AUTOSAR XML (schema 4-0-3)
package /ComponentTypes
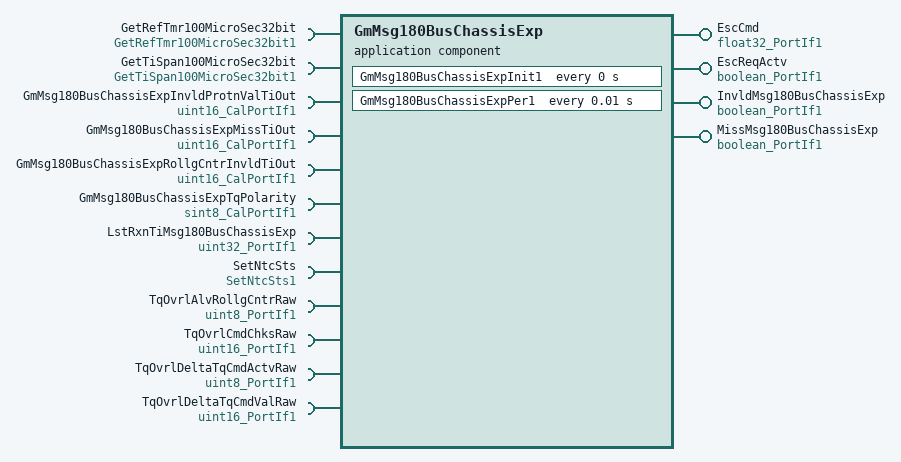
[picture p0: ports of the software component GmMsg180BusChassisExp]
  application sw component type GmMsg180BusChassisExp
    4 x provide port:
      EscCmd: nonqueued-sender-com-spec{data-element=Val, init-value=0}, provided-interface=float32_PortIf1
      EscReqActv: nonqueued-sender-com-spec{data-element=Logl, init-value=0}, provided-interface=boolean_PortIf1
      InvldMsg180BusChassisExp: nonqueued-sender-com-spec{data-element=Logl, init-value=0}, provided-interface=boolean_PortIf1
      MissMsg180BusChassisExp: nonqueued-sender-com-spec{data-element=Logl, init-value=0}, provided-interface=boolean_PortIf1
    12 x require port:
      GetRefTmr100MicroSec32bit: required-interface=GetRefTmr100MicroSec32bit1
      GetTiSpan100MicroSec32bit: required-interface=GetTiSpan100MicroSec32bit1
      GmMsg180BusChassisExpInvldProtnValTiOut: parameter-require-com-spec{init-value=500, parameter=Val}, required-interface=uint16_CalPortIf1
      GmMsg180BusChassisExpMissTiOut: parameter-require-com-spec{init-value=1000, parameter=Val}, required-interface=uint16_CalPortIf1
      GmMsg180BusChassisExpRollgCntrInvldTiOut: parameter-require-com-spec{init-value=500, parameter=Val}, required-interface=uint16_CalPortIf1
      GmMsg180BusChassisExpTqPolarity: parameter-require-com-spec{init-value=1, parameter=Val}, required-interface=sint8_CalPortIf1
      LstRxnTiMsg180BusChassisExp: nonqueued-receiver-com-spec{data-element=Val, filter=data-filter-type=ALWAYS, init-value=0}, required-interface=uint32_PortIf1
      SetNtcSts: required-interface=SetNtcSts1
      TqOvrlAlvRollgCntrRaw: nonqueued-receiver-com-spec{data-element=Val, filter=data-filter-type=ALWAYS, init-value=0}, required-interface=uint8_PortIf1
      TqOvrlCmdChksRaw: nonqueued-receiver-com-spec{data-element=Val, filter=data-filter-type=ALWAYS, init-value=0}, required-interface=uint16_PortIf1
      TqOvrlDeltaTqCmdActvRaw: nonqueued-receiver-com-spec{data-element=Val, filter=data-filter-type=ALWAYS, init-value=0}, required-interface=uint8_PortIf1
      TqOvrlDeltaTqCmdValRaw: nonqueued-receiver-com-spec{data-element=Val, filter=data-filter-type=ALWAYS, init-value=0}, required-interface=uint16_PortIf1
    behavior GmMsg180BusChassisExp_InternalBehavior: data-type-mapping=Nexteer
      ar-typed-per-instance-memorys:
        8 x data, all with sw-calibration-access=READ-ONLY:
          GmMsg180BusChassisExpInvldProtnValTmr: type=uint32
          GmMsg180BusChassisExpInvldRollgCntrTmr: type=uint32
          GmMsg180BusChassisExpPrevEscCmd: type=float32
          GmMsg180BusChassisExpPrevEscCmdActv: type=boolean
          GmMsg180BusChassisExpPrevInvld: type=boolean
          GmMsg180BusChassisExpPrevRollgCntrVal: type=uint8
          GmMsg180BusChassisExpPrevRxnTi: type=uint32
          GmMsg180BusChassisExpRollgCntrRst: type=boolean
      timing event GmMsg180BusChassisExp_InitEvent: start-on-event=GmMsg180BusChassisExpInit1, period=0
      timing event TMT_GM0C9HSPer1: start-on-event=GmMsg180BusChassisExpPer1, period=0.01
      runnable GmMsg180BusChassisExpInit1
      runnable GmMsg180BusChassisExpPer1
        data-receive-point-by-arguments:
          5 x access:
            REC_Msg0C9HSLstRxnTi_Val: accessed-variable=LstRxnTiMsg180BusChassisExp.Val
            REC_TqOvrlAlvRollgCntrRaw_Val: accessed-variable=TqOvrlAlvRollgCntrRaw.Val
            REC_TqOvrlCmdChksRaw_Val: accessed-variable=TqOvrlCmdChksRaw.Val
            REC_TqOvrlDeltaTqCmdActvRaw_Val: accessed-variable=TqOvrlDeltaTqCmdActvRaw.Val
            REC_TqOvrlDeltaTqCmdValRaw_Val: accessed-variable=TqOvrlDeltaTqCmdValRaw.Val
        data-send-points:
          4 x access:
            SEND_EscCmd_Val: accessed-variable=EscCmd.Val
            SEND_EscReqActv_Logl: accessed-variable=EscReqActv.Logl
            SEND_InvldMsg180BusChassisExp_Logl: accessed-variable=InvldMsg180BusChassisExp.Logl
            SEND_MissMsg180BusChassisExp_Logl: accessed-variable=MissMsg180BusChassisExp.Logl
        sync call SC_GetRefTmr100MicroSec32bit_Oper: operation=GetRefTmr100MicroSec32bit.Oper, timeout=0
        sync call SC_GetTiSpan100MicroSec32bit_Oper: operation=GetTiSpan100MicroSec32bit.Oper, timeout=0
        sync call SC_SetNtcSts_Oper: operation=SetNtcSts.Oper, timeout=0
  swc implementation GmMsg180BusChassisExp_Implementation: behavior=GmMsg180BusChassisExp_InternalBehavior
    code-descriptors:
      code Default: artifact-descriptors=autosar-engineering-object={short-label=Default, category=SWSRC}
